VERSION ""

NS_ :

BS_:

BO_ 928 EPB_STATUS: 8 XXX
 SG_ EPB_BRAKE : 16|1@1+ (1,0) [0|3] "" XXX

BO_ 1104 SEATBELT_STATUS: 8 XXX
 SG_ DRIVER_SEAT_BELT_ONOFF : 21|1@0+ (1,0) [0|3] "" XXX

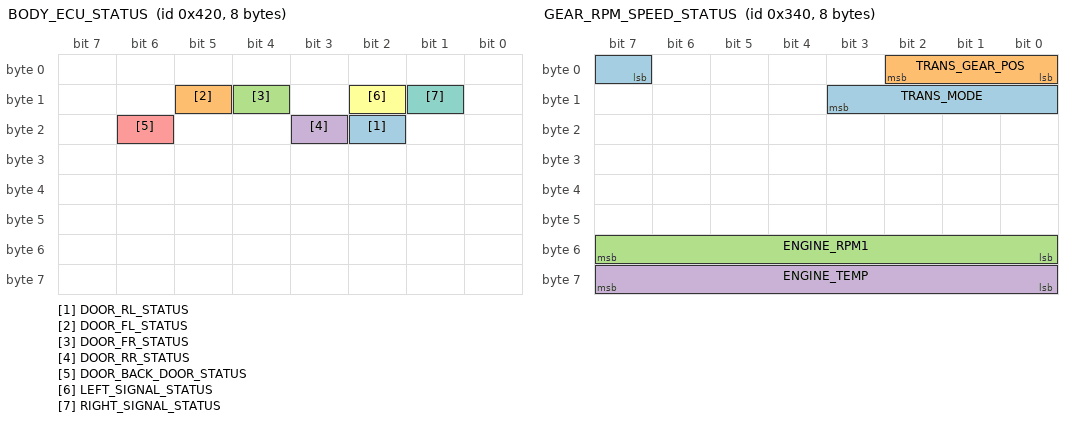
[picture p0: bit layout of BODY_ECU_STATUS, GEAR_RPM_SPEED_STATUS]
BO_ 1056 BODY_ECU_STATUS: 8 XXX
 SG_ DOOR_RL_STATUS : 18|1@0+ (1,0) [0|255] "" XXX
 SG_ DOOR_FL_STATUS : 13|1@0+ (1,0) [0|1] "" XXX
 SG_ DOOR_FR_STATUS : 12|1@0+ (1,0) [0|1] "" XXX
 SG_ DOOR_RR_STATUS : 19|1@0+ (1,0) [0|1] "" XXX
 SG_ DOOR_BACK_DOOR_STATUS : 22|1@0+ (1,0) [0|1] "" XXX
 SG_ LEFT_SIGNAL_STATUS : 10|1@0+ (1,0) [0|1] "" XXX
 SG_ RIGHT_SIGNAL_STATUS : 9|1@0+ (1,0) [0|1] "" XXX

BO_ 832 GEAR_RPM_SPEED_STATUS: 8 XXX
 SG_ TRANS_MODE : 7|5@1+ (1,0) [0|0] "" XXX
 SG_ TRANS_GEAR_POS : 2|3@0+ (1,0) [0|1] "" XXX
 SG_ ENGINE_RPM1 : 55|8@0+ (1,0) [0|255] "" XXX
 SG_ ENGINE_TEMP : 63|8@0+ (1,0) [0|255] "" XXX

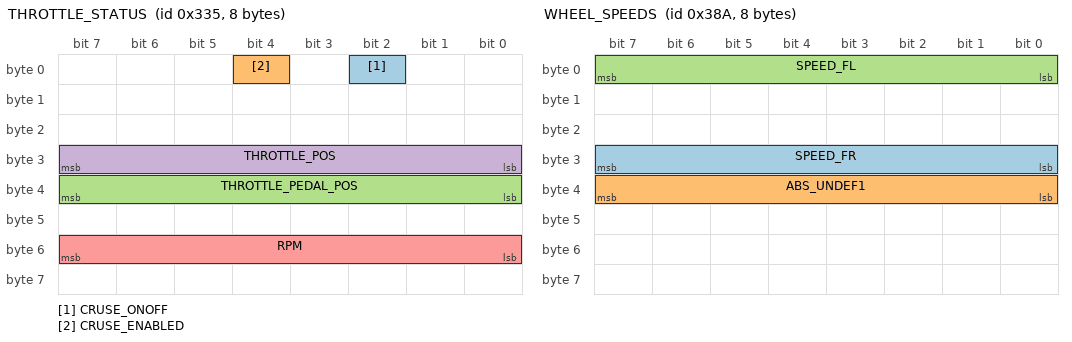
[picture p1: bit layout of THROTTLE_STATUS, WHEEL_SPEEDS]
BO_ 821 THROTTLE_STATUS: 8 XXX
 SG_ CRUSE_ONOFF : 2|1@0+ (1,0) [0|1] "on/off" XXX
 SG_ CRUSE_ENABLED : 4|1@0+ (1,0) [0|1] "" XXX
 SG_ THROTTLE_PEDAL_POS : 32|8@1+ (1,0) [0|255] "" XXX
 SG_ THROTTLE_POS : 24|8@1+ (1,0) [0|255] "" XXX
 SG_ RPM : 48|8@1- (1,0) [0|65535] "" XXX

BO_ 922 STEERING_ANGLE_STATUS: 8 XXX
 SG_ STEER_ANGLE_9000 : 7|16@0- (1,0) [0|65535] "" XXX

BO_ 906 WHEEL_SPEEDS: 8 XXX
 SG_ SPEED_FR : 24|8@1+ (1,0) [0|255] "" XXX
 SG_ ABS_UNDEF1 : 32|8@1+ (1,0) [0|255] "" XXX
 SG_ SPEED_FL : 0|8@1+ (1,0) [0|255] "" XXX

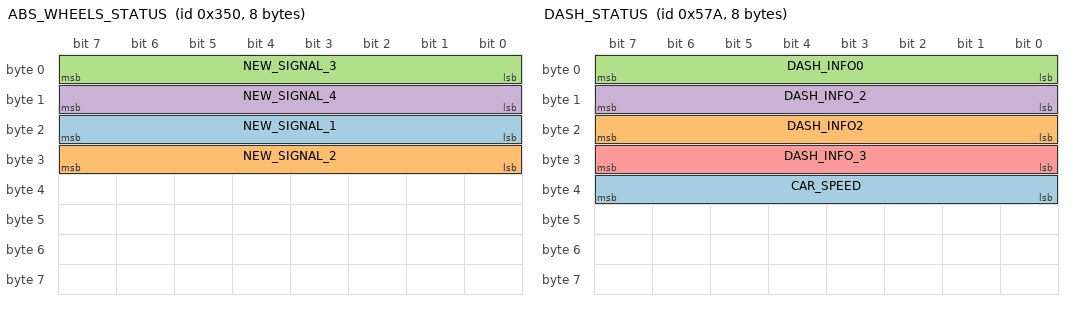
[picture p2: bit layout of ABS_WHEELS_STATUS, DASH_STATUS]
BO_ 848 ABS_WHEELS_STATUS: 8 XXX
 SG_ NEW_SIGNAL_1 : 23|8@0+ (1,0) [0|255] "" XXX
 SG_ NEW_SIGNAL_2 : 31|8@0+ (1,0) [0|255] "" XXX
 SG_ NEW_SIGNAL_3 : 7|8@0+ (1,0) [0|255] "" XXX
 SG_ NEW_SIGNAL_4 : 15|8@0+ (1,0) [0|255] "" XXX

BO_ 1402 DASH_STATUS: 8 XXX
 SG_ CAR_SPEED : 32|8@1+ (1,0) [0|255] "" XXX
 SG_ DASH_INFO2 : 16|8@1+ (1,0) [0|255] "" XXX
 SG_ DASH_INFO0 : 0|8@1+ (1,0) [0|255] "" XXX
 SG_ DASH_INFO_2 : 15|8@0+ (1,0) [0|255] "" XXX
 SG_ DASH_INFO_3 : 31|8@0+ (1,0) [0|255] "" XXX

BO_ 1306 _SPEEDX: 8 XXX
 SG_ DASH_CAR_SPEED : 7|9@0+ (1,0) [0|255] "" XXX

BO_ 1296 undefined: 8 XXX

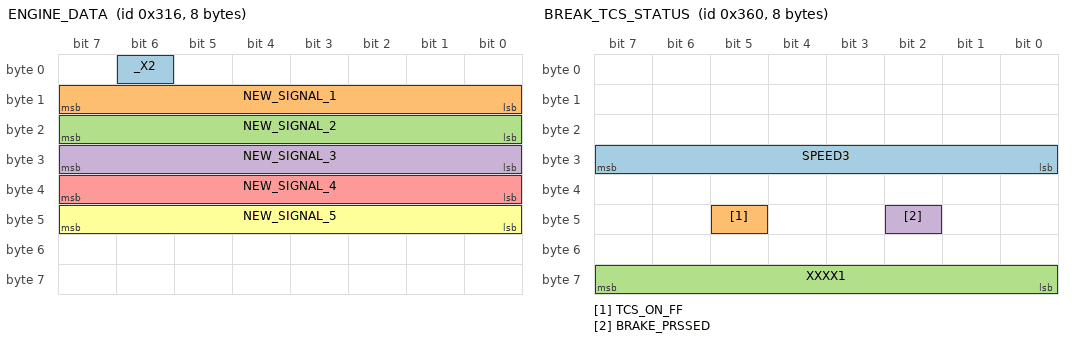
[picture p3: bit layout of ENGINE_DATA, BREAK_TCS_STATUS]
BO_ 790 ENGINE_DATA: 8 XXX
 SG_ _X2 : 6|1@0+ (1,0) [0|1] "" XXX
 SG_ NEW_SIGNAL_1 : 15|8@0+ (1,0) [0|255] "" XXX
 SG_ NEW_SIGNAL_2 : 23|8@0+ (1,0) [0|255] "" XXX
 SG_ NEW_SIGNAL_3 : 31|8@0+ (1,0) [0|255] "" XXX
 SG_ NEW_SIGNAL_4 : 39|8@0+ (1,0) [0|255] "" XXX
 SG_ NEW_SIGNAL_5 : 47|8@0+ (1,0) [0|255] "" XXX

BO_ 1313 undefined_2: 8 XXX

BO_ 1312 __trigger_every_range: 8 XXX
 SG_ __SIGNAL_every_interval : 4|1@0+ (1,0) [0|1] "" XXX

BO_ 896 undefined_3: 8 XXX
 SG_ NEW_SIGNAL_1 : 32|4@1+ (1,0) [0|15] "" XXX

BO_ 809 undefined_4: 8 XXX

BO_ 864 BREAK_TCS_STATUS: 8 XXX
 SG_ SPEED3 : 24|8@1+ (1,0) [0|255] "" XXX
 SG_ TCS_ON_FF : 45|1@0+ (1,0) [0|1] "" XXX
 SG_ XXXX1 : 63|8@0+ (1,0) [0|255] "" XXX
 SG_ BRAKE_PRSSED : 42|1@0+ (1,0) [0|1] "" XXX

BO_ 842 undefined_5: 8 XXX

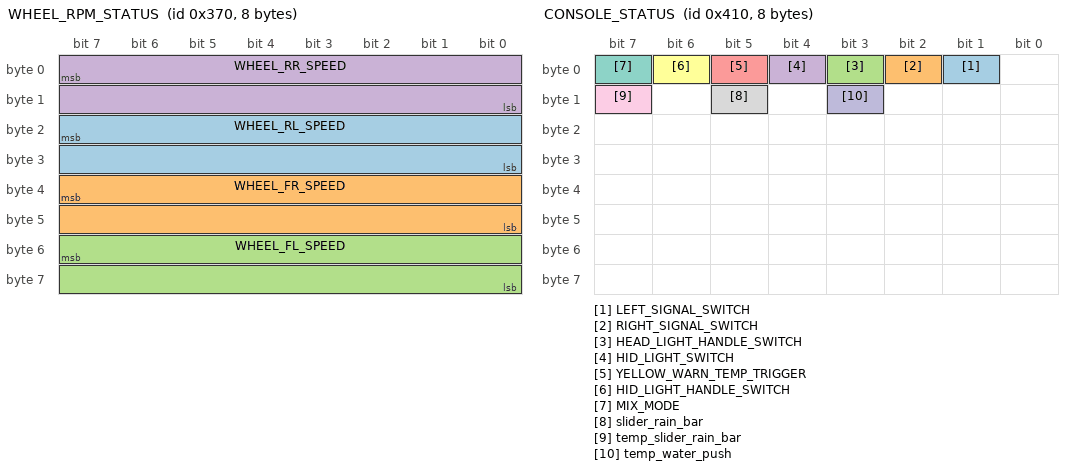
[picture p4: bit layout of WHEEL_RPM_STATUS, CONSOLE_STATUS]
BO_ 880 WHEEL_RPM_STATUS: 8 XXX
 SG_ WHEEL_RL_SPEED : 23|16@0+ (1,0) [0|255] "" XXX
 SG_ WHEEL_FR_SPEED : 39|16@0+ (1,0) [0|255] "" XXX
 SG_ WHEEL_FL_SPEED : 55|16@0+ (1,0) [0|255] "" XXX
 SG_ WHEEL_RR_SPEED : 7|16@0- (1,0) [0|255] "" XXX

BO_ 1040 CONSOLE_STATUS: 8 XXX
 SG_ LEFT_SIGNAL_SWITCH : 1|1@0+ (1,0) [0|1] "" XXX
 SG_ RIGHT_SIGNAL_SWITCH : 2|1@0+ (1,0) [0|1] "" XXX
 SG_ HEAD_LIGHT_HANDLE_SWITCH : 3|1@0+ (1,0) [0|1] "" XXX
 SG_ HID_LIGHT_SWITCH : 4|1@0+ (1,0) [0|1] "" XXX
 SG_ YELLOW_WARN_TEMP_TRIGGER : 5|1@0+ (1,0) [0|1] "" XXX
 SG_ HID_LIGHT_HANDLE_SWITCH : 6|1@0+ (1,0) [0|1] "" XXX
 SG_ MIX_MODE : 7|1@0+ (1,0) [0|1] "" XXX
 SG_ slider_rain_bar : 13|1@0+ (1,0) [0|1] "" XXX
 SG_ temp_slider_rain_bar : 15|1@0+ (1,0) [0|1] "" XXX
 SG_ temp_water_push : 11|1@0+ (1,0) [0|1] "" XXX

BO_ 1120 HAVC_STATUS: 8 XXX
 SG_ HAVC_TEMP : 32|8@1+ (1,0) [0|255] "" XXX

CM_ "AUTOGENERATED FILE, DO NOT EDIT";

CM_ "Imported file _stellantis_common_ram_dt_generated.dbc starts here";
CM_ "Generated from _stellantis_common.dbc"

CM_ SG_ 258 STEERING_ANGLE_HP "Steering angle high precision";
CM_ SG_ 264 ENGINE_TORQUE "Effective engine torque";
CM_ SG_ 264 EXPECTED_ENGINE_TORQUE "Expected Engine Torque based on target engine speed";
CM_ SG_ 678 LKAS_ICON_COLOR "3 is yellow, 2 is green, 1 is white, 0 is null";
CM_ SG_ 678 LKAS_LANE_LINES "0x01 transparent lines, 0x02 left white, 0x03 right white, 0x04 left yellow with car on top, 0x05 left yellow with car on top, 0x06 both white, 0x07 left yellow, 0x08 left yellow right white, 0x09 right yellow, 0x0a right yellow left white, 0x0b left yellow with car on top right white, 0x0c right yellow with car on top left white, (0x00, 0x0d, 0x0e, 0x0f) null";
CM_ SG_ 678 LKAS_ALERTS "(0x01, 0x02) lane sense off, (0x03, 0x04, 0x06) place hands on steering wheel, 0x07 lane departure detected + place hands on steering wheel, (0x08, 0x09) lane sense unavailable + clean front windshield, 0x0b lane sense and auto high beam unavailable + clean front windshield, 0x0c lane sense unavailable + service required, (0x00, 0x05, 0x0a, 0x0d, 0x0e, 0x0f) null";

CM_ "chrysler_ram_dt.dbc starts here";

CM_ SG_ 133 ACTUAL_GEAR "0xd = P, 0x1-8 = D (actual gear), 0xb = R or N?? TODO find R vs N";
CM_ SG_ 153 ACC_Engaged "SENT BY FORWARD CAMERA 1 = ACTIVE, 3 = ENGAGED, 0 = DISENGAGED/OFF";
CM_ SG_ 166 LKAS_CONTROL_BIT "0=IDLE, 1=HAS 2=LKAS 3=ABSD, 4=TJA, 7=SNA";
CM_ SG_ 250 Auto_High_Beam "1 = HIGH BEAMS OK 0 = HIGH BEAMS OFF ";
CM_ SG_ 250 LKAS_LANE_LINES "9 = LEFT CAUTION, 11 = VERY LEFT CAUTION 10 = RIGHT CAUTION, 14 = VERY RIGHT, 4 = NO LINES DETECTED, 3 = LINES DETECTED, SYSTEM ACTIVE";
CM_ SG_ 464 Driver_Seatbelt_Status "1 unbuckled 0 buckled";
